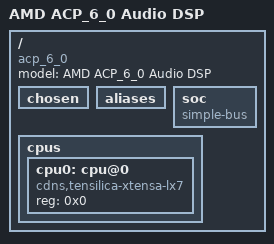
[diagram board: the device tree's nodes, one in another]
/dts-v1/;

/* node '/' defined in zephyr/dts/common/skeleton.dtsi:9 */
/ {
	#address-cells = < 0x1 >;         /* in zephyr/dts/common/skeleton.dtsi:10 */
	#size-cells = < 0x1 >;            /* in zephyr/dts/common/skeleton.dtsi:11 */
	model = "AMD ACP_6_0  Audio DSP"; /* in zephyr/boards/amd/acp_6_0_adsp/acp_6_0_adsp.dts:12 */
	compatible = "acp_6_0";           /* in zephyr/boards/amd/acp_6_0_adsp/acp_6_0_adsp.dts:13 */

	/* node '/chosen' defined in zephyr/dts/common/skeleton.dtsi:13 */
	chosen {
	};

	/* node '/aliases' defined in zephyr/dts/common/skeleton.dtsi:15 */
	aliases {
	};

	/* node '/soc' defined in zephyr/dts/xtensa/xtensa.dtsi:10 */
	soc {
		#address-cells = < 0x1 >;  /* in zephyr/dts/xtensa/xtensa.dtsi:11 */
		#size-cells = < 0x1 >;     /* in zephyr/dts/xtensa/xtensa.dtsi:12 */
		compatible = "simple-bus"; /* in zephyr/dts/xtensa/xtensa.dtsi:13 */
		ranges;                    /* in zephyr/dts/xtensa/xtensa.dtsi:14 */
	};

	/* node '/cpus' defined in zephyr/dts/xtensa/amd/acp_6_0.dtsi:11 */
	cpus {
		#address-cells = < 0x1 >; /* in zephyr/dts/xtensa/amd/acp_6_0.dtsi:12 */
		#size-cells = < 0x0 >;    /* in zephyr/dts/xtensa/amd/acp_6_0.dtsi:13 */

		/* node '/cpus/cpu@0' defined in zephyr/dts/xtensa/amd/acp_6_0.dtsi:15 */
		cpu0: cpu@0 {
			device_type = "cpu";                      /* in zephyr/dts/xtensa/amd/acp_6_0.dtsi:16 */
			compatible = "cdns,tensilica-xtensa-lx7"; /* in zephyr/dts/xtensa/amd/acp_6_0.dtsi:17 */
			reg = < 0x0 >;                            /* in zephyr/dts/xtensa/amd/acp_6_0.dtsi:18 */
		};
	};
};
